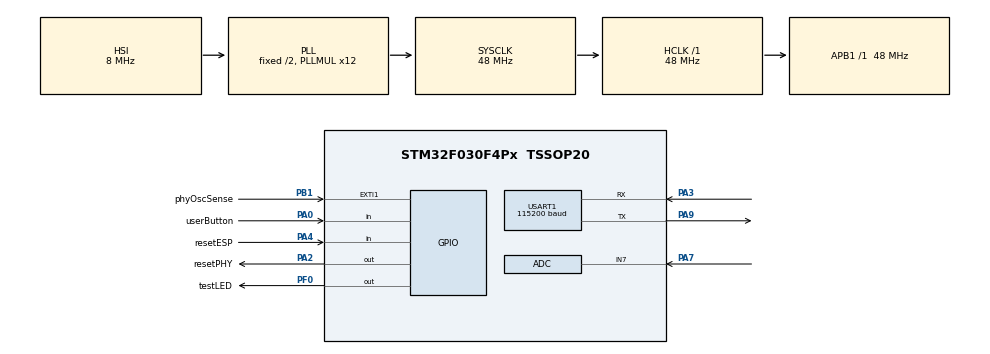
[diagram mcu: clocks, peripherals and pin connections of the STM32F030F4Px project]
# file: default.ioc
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Mcu.Family=STM32F0
Mcu.Name=STM32F030F4Px
Mcu.Package=TSSOP20
PA0.GPIO_Label=userButton
PA0.Signal=GPIO_Input
PA2.GPIO_Label=resetPHY
PA2.PinState=GPIO_PIN_RESET
PA2.Signal=GPIO_Output
PA3.Mode=Asynchronous
PA3.Signal=USART1_RX
PA4.GPIO_Label=resetESP
PA4.Signal=GPIO_Input
PA7.Mode=IN7
PA7.Signal=ADC_IN7
PA9.Mode=Asynchronous
PA9.Signal=USART1_TX
PB1.GPIO_Label=phyOscSense
PB1.GPIO_ModeDefaultEXTI=GPIO_MODE_IT_RISING_FALLING
PB1.Signal=GPXTI1
PF0-OSC_IN.GPIO_Label=testLED
PF0-OSC_IN.Signal=GPIO_Output
ProjectManager.HeapSize=0x200
ProjectManager.StackSize=0x400
ProjectManager.TargetToolchain=STM32CubeIDE
RCC.AHBFreq_Value=48000000
RCC.APB1Freq_Value=48000000
RCC.APB1TimFreq_Value=48000000
RCC.HCLKFreq_Value=48000000
RCC.PLLMUL=RCC_PLL_MUL12
RCC.SYSCLKFreq_VALUE=48000000
RCC.SYSCLKSource=RCC_SYSCLKSOURCE_PLLCLK
USART1.BaudRate=115200
USART1.VirtualMode-Asynchronous=VM_ASYNC
board=custom

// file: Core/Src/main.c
/* USER CODE BEGIN Header */
/**
  ******************************************************************************
  * @file           : main.c
  * @brief          : Main program body
  ******************************************************************************
  * @attention
  *
  * <h2><center>&copy; Copyright (c) 2019 STMicroelectronics.
  * All rights reserved.</center></h2>
  *
  * This software component is licensed by ST under BSD 3-Clause license,
  * the "License"; You may not use this file except in compliance with the
  * License. You may obtain a copy of the License at:
  *                        opensource.org/licenses/BSD-3-Clause
  *
  ******************************************************************************
  */
/* USER CODE END Header */

#include "main.h"
#include "adc.h"
#include "usart.h"
#include "gpio.h"

/* USER CODE BEGIN Includes */
#include "main_app.h"
/* USER CODE END Includes */

void SystemClock_Config(void);

int main(void)
{
  /* USER CODE BEGIN 1 */
  mainAppInitPreHAL();  //Initialization called before HAL init
  /* USER CODE END 1 */

  /* MCU Configuration--------------------------------------------------------*/

  /* Reset of all peripherals, Initializes the Flash interface and the Systick. */
  HAL_Init();

  /* Configure the system clock */
  SystemClock_Config();

  /* USER CODE BEGIN SysInit */
  mainAppInit();
  /* USER CODE END SysInit */

  /* Initialize all configured peripherals */
  MX_GPIO_Init();
  MX_USART1_UART_Init();
  MX_ADC_Init();
  /* USER CODE BEGIN 2 */
  mainAppPreLoop();
  /* USER CODE END 2 */

  /* Infinite loop */
  /* USER CODE BEGIN WHILE */
  while (1)
  {
    mainAppLoop();
    /* USER CODE END WHILE */

  }
}

void SystemClock_Config(void)
{
  RCC_OscInitTypeDef RCC_OscInitStruct = {0};
  RCC_ClkInitTypeDef RCC_ClkInitStruct = {0};
  RCC_PeriphCLKInitTypeDef PeriphClkInit = {0};

  /** Initializes the CPU, AHB and APB busses clocks
  */
  RCC_OscInitStruct.OscillatorType = RCC_OSCILLATORTYPE_HSI|RCC_OSCILLATORTYPE_HSI14;
  RCC_OscInitStruct.HSIState = RCC_HSI_ON;
  RCC_OscInitStruct.HSI14State = RCC_HSI14_ON;
  RCC_OscInitStruct.HSICalibrationValue = RCC_HSICALIBRATION_DEFAULT;
  RCC_OscInitStruct.HSI14CalibrationValue = 16;
  RCC_OscInitStruct.PLL.PLLState = RCC_PLL_ON;
  RCC_OscInitStruct.PLL.PLLSource = RCC_PLLSOURCE_HSI;
  RCC_OscInitStruct.PLL.PLLMUL = RCC_PLL_MUL12;
  RCC_OscInitStruct.PLL.PREDIV = RCC_PREDIV_DIV1;
  if (HAL_RCC_OscConfig(&RCC_OscInitStruct) != HAL_OK)
  {
    Error_Handler();
  }
  /** Initializes the CPU, AHB and APB busses clocks
  */
  RCC_ClkInitStruct.ClockType = RCC_CLOCKTYPE_HCLK|RCC_CLOCKTYPE_SYSCLK
                              |RCC_CLOCKTYPE_PCLK1;
  RCC_ClkInitStruct.SYSCLKSource = RCC_SYSCLKSOURCE_PLLCLK;
  RCC_ClkInitStruct.AHBCLKDivider = RCC_SYSCLK_DIV1;
  RCC_ClkInitStruct.APB1CLKDivider = RCC_HCLK_DIV1;

  if (HAL_RCC_ClockConfig(&RCC_ClkInitStruct, FLASH_LATENCY_1) != HAL_OK)
  {
    Error_Handler();
  }
  PeriphClkInit.PeriphClockSelection = RCC_PERIPHCLK_USART1;
  PeriphClkInit.Usart1ClockSelection = RCC_USART1CLKSOURCE_PCLK1;
  if (HAL_RCCEx_PeriphCLKConfig(&PeriphClkInit) != HAL_OK)
  {
    Error_Handler();
  }
}

void Error_Handler(void)
{
}

/************************ (C) COPYRIGHT STMicroelectronics *****END OF FILE****/
